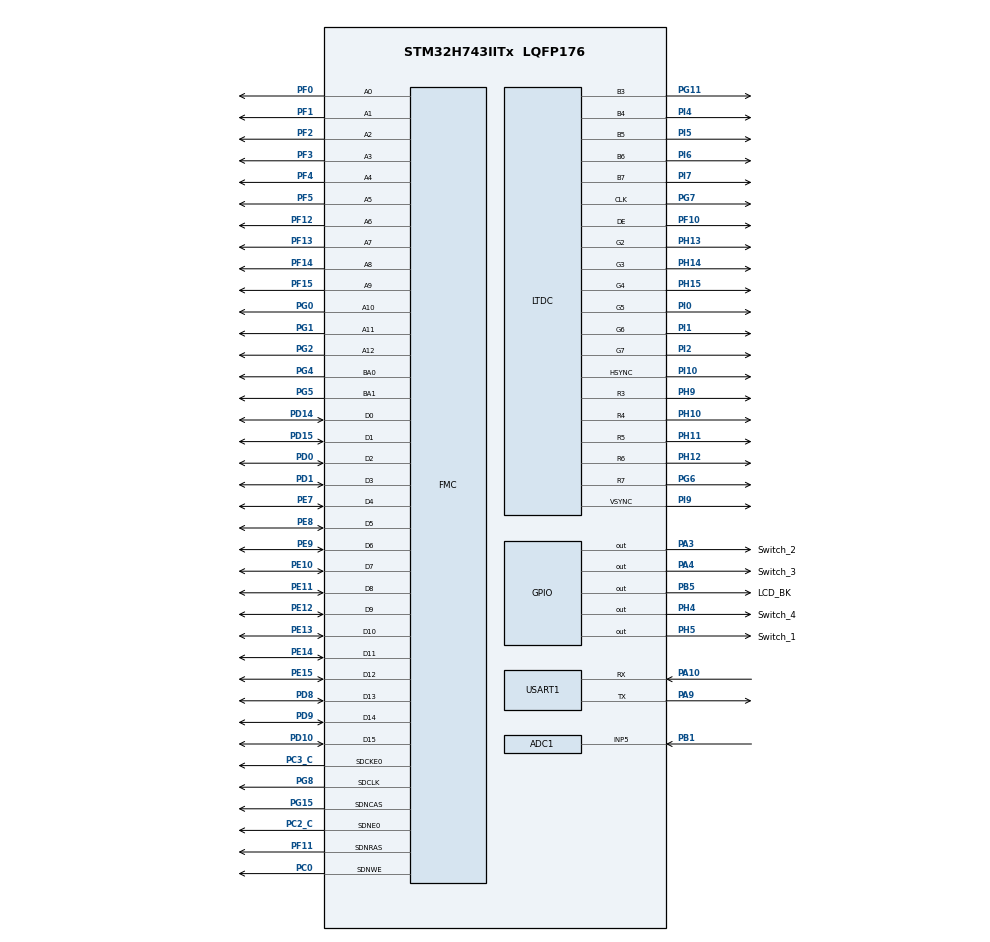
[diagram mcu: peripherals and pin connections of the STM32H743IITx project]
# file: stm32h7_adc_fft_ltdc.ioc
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ADC1.Channel-5\#ChannelRegularConversion=ADC_CHANNEL_5
ADC1.ClockPrescaler=ADC_CLOCK_ASYNC_DIV4
ADC1.ContinuousConvMode=DISABLE
ADC1.ConversionDataManagement=ADC_CONVERSIONDATA_DMA_CIRCULAR
ADC1.EOCSelection=ADC_EOC_SEQ_CONV
ADC1.ExternalTrigConv=ADC_EXTERNALTRIG_T3_TRGO
ADC1.NbrOfConversion=1
ADC1.NbrOfConversionFlag=1
ADC1.OffsetNumber-5\#ChannelRegularConversion=ADC_OFFSET_NONE
ADC1.OffsetSignedSaturation-5\#ChannelRegularConversion=DISABLE
ADC1.Overrun=ADC_OVR_DATA_OVERWRITTEN
ADC1.OversamplingMode=DISABLE
ADC1.Rank-5\#ChannelRegularConversion=1
ADC1.Resolution=ADC_RESOLUTION_16B
ADC1.SamplingTime-5\#ChannelRegularConversion=ADC_SAMPLETIME_64CYCLES_5
ADC1.master=1
CORTEX_M7.CPU_DCache=Disabled
CORTEX_M7.CPU_ICache=Disabled
CORTEX_M7.MPU_Control=__NULL
CORTEX_M7.default_mode_Activation=1
DMA2D.ColorMode=DMA2D_OUTPUT_RGB565
Dma.ADC1.0.Direction=DMA_PERIPH_TO_MEMORY
Dma.ADC1.0.EventEnable=DISABLE
Dma.ADC1.0.FIFOMode=DMA_FIFOMODE_DISABLE
Dma.ADC1.0.Instance=DMA1_Stream0
Dma.ADC1.0.MemDataAlignment=DMA_MDATAALIGN_HALFWORD
Dma.ADC1.0.MemInc=DMA_MINC_ENABLE
Dma.ADC1.0.Mode=DMA_NORMAL
Dma.ADC1.0.PeriphDataAlignment=DMA_PDATAALIGN_HALFWORD
Dma.ADC1.0.PeriphInc=DMA_PINC_DISABLE
Dma.ADC1.0.Polarity=HAL_DMAMUX_REQ_GEN_RISING
Dma.ADC1.0.Priority=DMA_PRIORITY_LOW
Dma.ADC1.0.RequestNumber=1
Dma.ADC1.0.SignalID=NONE
Dma.ADC1.0.SyncEnable=DISABLE
Dma.ADC1.0.SyncPolarity=HAL_DMAMUX_SYNC_NO_EVENT
Dma.ADC1.0.SyncRequestNumber=1
Dma.ADC1.0.SyncSignalID=NONE
Dma.Request0=ADC1
FMC.CASLatency1=FMC_SDRAM_CAS_LATENCY_3
FMC.ColumnBitsNumber1=FMC_SDRAM_COLUMN_BITS_NUM_9
FMC.ExitSelfRefreshDelay1=8
FMC.LoadToActiveDelay1=2
FMC.RCDDelay1=2
FMC.RPDelay1=2
FMC.ReadBurst1=FMC_SDRAM_RBURST_ENABLE
FMC.ReadPipeDelay1=FMC_SDRAM_RPIPE_DELAY_1
FMC.RowCycleDelay1=7
FMC.RowCycleDelay2=7
FMC.SDClockPeriod1=FMC_SDRAM_CLOCK_PERIOD_2
FMC.SelfRefreshTime1=6
FMC.WriteRecoveryTime1=5
LTDC.ActiveH=PIXELS_H
LTDC.ActiveW=PIXELS_W
LTDC.Alpha_L0=255
LTDC.Blue=0
LTDC.Blue_L0=0
LTDC.FBStartAdress_L0=0xc0000000
LTDC.Green=0
LTDC.HBP=140
LTDC.HFP=160
LTDC.HSync=20
LTDC.ImageHeight_L0=600
LTDC.ImageWidth_L0=1024
LTDC.Layers=0
LTDC.PixelFormat_L0=LTDC_PIXEL_FORMAT_RGB565
LTDC.Red=0
LTDC.VBP=20
LTDC.VFP=12
LTDC.VSync=3
LTDC.WindowX1_L0=PIXELS_W
LTDC.WindowY1_L0=PIXELS_H
Mcu.Family=STM32H7
Mcu.Name=STM32H743IITx
Mcu.Package=LQFP176
Mcu.UserConstants=PIXELS_DIR,1;PIXELS_H,600;PIXELS_W,1024;LTDC_BUFF_ADDR,0XC0000000
NVIC.ADC_IRQn=true\:0\:0\:false\:false\:true\:true\:true\:true
NVIC.DMA1_Stream0_IRQn=true\:2\:0\:true\:false\:true\:true\:true\:true
NVIC.DMA2D_IRQn=true\:0\:0\:false\:false\:true\:true\:true\:true
NVIC.PriorityGroup=NVIC_PRIORITYGROUP_4
NVIC.USART1_IRQn=true\:0\:0\:false\:false\:true\:true\:true\:true
PA10.Mode=Asynchronous
PA10.Signal=USART1_RX
PA3.GPIO_Label=Switch_2
PA3.GPIO_PuPd=GPIO_PULLDOWN
PA3.Signal=GPIO_Output
PA4.GPIO_Label=Switch_3
PA4.GPIO_PuPd=GPIO_PULLDOWN
PA4.Signal=GPIO_Output
PA9.Mode=Asynchronous
PA9.Signal=USART1_TX
PB0.Signal=ADCx_INN5
PB1.Signal=ADCx_INP5
PB5.GPIO_Label=LCD_BK
PB5.GPIO_PuPd=GPIO_PULLDOWN
PB5.Signal=GPIO_Output
PC0.Signal=FMC_SDNWE
PC14-OSC32_IN\ (OSC32_IN).Mode=LSE-External-Oscillator
PC14-OSC32_IN\ (OSC32_IN).Signal=RCC_OSC32_IN
PC15-OSC32_OUT\ (OSC32_OUT).Mode=LSE-External-Oscillator
PC15-OSC32_OUT\ (OSC32_OUT).Signal=RCC_OSC32_OUT
PC2_C.Mode=SdramChipSelect1_1
PC2_C.Signal=FMC_SDNE0
PC3_C.Mode=SdramChipSelect1_1
PC3_C.Signal=FMC_SDCKE0
PD0.Signal=FMC_D2_DA2
PD1.Signal=FMC_D3_DA3
PD10.Signal=FMC_D15_DA15
PD14.Signal=FMC_D0_DA0
PD15.Signal=FMC_D1_DA1
PD8.Signal=FMC_D13_DA13
PD9.Signal=FMC_D14_DA14
PE0.Signal=FMC_NBL0
PE1.Signal=FMC_NBL1
PE10.Signal=FMC_D7_DA7
PE11.Signal=FMC_D8_DA8
PE12.Signal=FMC_D9_DA9
PE13.Signal=FMC_D10_DA10
PE14.Signal=FMC_D11_DA11
PE15.Signal=FMC_D12_DA12
PE7.Signal=FMC_D4_DA4
PE8.Signal=FMC_D5_DA5
PE9.Signal=FMC_D6_DA6
PF0.Signal=FMC_A0
PF1.Signal=FMC_A1
PF10.GPIO_Speed=GPIO_SPEED_FREQ_VERY_HIGH
PF10.Mode=RGB565
PF10.Signal=LTDC_DE
PF11.Signal=FMC_SDNRAS
PF12.Signal=FMC_A6
PF13.Signal=FMC_A7
PF14.Signal=FMC_A8
PF15.Signal=FMC_A9
PF2.Signal=FMC_A2
PF3.Signal=FMC_A3
PF4.Signal=FMC_A4
PF5.Signal=FMC_A5
PG0.Signal=FMC_A10
PG1.Signal=FMC_A11
PG11.GPIO_Speed=GPIO_SPEED_FREQ_VERY_HIGH
PG11.Mode=RGB565
PG11.Signal=LTDC_B3
PG15.Signal=FMC_SDNCAS
PG2.Signal=FMC_A12
PG4.Signal=FMC_A14_BA0
PG5.Signal=FMC_A15_BA1
PG6.GPIO_Speed=GPIO_SPEED_FREQ_VERY_HIGH
PG6.Mode=RGB565
PG6.Signal=LTDC_R7
PG7.GPIO_Speed=GPIO_SPEED_FREQ_VERY_HIGH
PG7.Mode=RGB565
PG7.Signal=LTDC_CLK
PG8.Signal=FMC_SDCLK
PH0-OSC_IN\ (PH0).Mode=HSE-External-Oscillator
PH0-OSC_IN\ (PH0).Signal=RCC_OSC_IN
PH1-OSC_OUT\ (PH1).Mode=HSE-External-Oscillator
PH1-OSC_OUT\ (PH1).Signal=RCC_OSC_OUT
PH10.GPIO_Speed=GPIO_SPEED_FREQ_VERY_HIGH
PH10.Mode=RGB565
PH10.Signal=LTDC_R4
PH11.GPIO_Speed=GPIO_SPEED_FREQ_VERY_HIGH
PH11.Mode=RGB565
PH11.Signal=LTDC_R5
PH12.GPIO_Speed=GPIO_SPEED_FREQ_VERY_HIGH
PH12.Mode=RGB565
PH12.Signal=LTDC_R6
PH13.GPIO_Speed=GPIO_SPEED_FREQ_VERY_HIGH
PH13.Mode=RGB565
PH13.Signal=LTDC_G2
PH14.GPIO_Speed=GPIO_SPEED_FREQ_VERY_HIGH
PH14.Mode=RGB565
PH14.Signal=LTDC_G3
PH15.GPIO_Speed=GPIO_SPEED_FREQ_VERY_HIGH
PH15.Mode=RGB565
PH15.Signal=LTDC_G4
PH4.GPIO_Label=Switch_4
PH4.GPIO_PuPd=GPIO_PULLDOWN
PH4.Signal=GPIO_Output
PH5.GPIO_Label=Switch_1
PH5.GPIO_PuPd=GPIO_PULLDOWN
PH5.Signal=GPIO_Output
PH9.GPIO_Speed=GPIO_SPEED_FREQ_VERY_HIGH
PH9.Mode=RGB565
PH9.Signal=LTDC_R3
PI0.GPIO_Speed=GPIO_SPEED_FREQ_VERY_HIGH
PI0.Mode=RGB565
PI0.Signal=LTDC_G5
PI1.GPIO_Speed=GPIO_SPEED_FREQ_VERY_HIGH
PI1.Mode=RGB565
PI1.Signal=LTDC_G6
PI10.GPIO_Speed=GPIO_SPEED_FREQ_VERY_HIGH
PI10.Mode=RGB565
PI10.Signal=LTDC_HSYNC
PI2.GPIO_Speed=GPIO_SPEED_FREQ_VERY_HIGH
PI2.Mode=RGB565
PI2.Signal=LTDC_G7
PI4.GPIO_Speed=GPIO_SPEED_FREQ_VERY_HIGH
PI4.Mode=RGB565
PI4.Signal=LTDC_B4
PI5.GPIO_Speed=GPIO_SPEED_FREQ_VERY_HIGH
PI5.Mode=RGB565
PI5.Signal=LTDC_B5
PI6.GPIO_Speed=GPIO_SPEED_FREQ_VERY_HIGH
PI6.Mode=RGB565
PI6.Signal=LTDC_B6
PI7.GPIO_Speed=GPIO_SPEED_FREQ_VERY_HIGH
PI7.Mode=RGB565
PI7.Signal=LTDC_B7
PI9.GPIO_Speed=GPIO_SPEED_FREQ_VERY_HIGH
PI9.Mode=RGB565
PI9.Signal=LTDC_VSYNC
ProjectManager.HeapSize=0x600
ProjectManager.StackSize=0x600
ProjectManager.TargetToolchain=STM32CubeIDE
RCC.ADCFreq_Value=72000000
RCC.APB1Freq_Value=120000000
RCC.APB2Freq_Value=120000000
RCC.APB3Freq_Value=120000000
RCC.APB4Freq_Value=120000000
RCC.CKPERSourceSelection=RCC_CLKPSOURCE_HSE
RCC.CortexFreq_Value=480000000
RCC.D1PPRE=RCC_APB3_DIV2
RCC.D2PPRE1=RCC_APB1_DIV2
RCC.D2PPRE2=RCC_APB2_DIV2
RCC.D3PPRE=RCC_APB4_DIV2
RCC.DIVM1=5
RCC.DIVM2=5
RCC.DIVM3=1
RCC.DIVN1=192
RCC.DIVN2=72
RCC.DIVN3=9
RCC.DIVP2=5
RCC.DIVR3=5
RCC.HCLKFreq_Value=240000000
RCC.HPRE=RCC_HCLK_DIV2
RCC.PLL2FRACN=0
RCC.PLL3FRACN=0
RCC.PLLFRACN=0
RCC.PLLSourceVirtual=RCC_PLLSOURCE_HSE
RCC.PWR_Regulator_Voltage_Scale=PWR_REGULATOR_VOLTAGE_SCALE0
RCC.SYSCLKFreq_VALUE=480000000
RCC.SYSCLKSource=RCC_SYSCLKSOURCE_PLLCLK
RCC.USBFreq_Value=480000000
SH.ADCx_INN5.0=ADC1_INN5
SH.ADCx_INP5.0=ADC1_INP5,IN5-Single-Ended
SH.FMC_A0.0=FMC_A0,13b-sda1
SH.FMC_A1.0=FMC_A1,13b-sda1
SH.FMC_A10.0=FMC_A10,13b-sda1
SH.FMC_A11.0=FMC_A11,13b-sda1
SH.FMC_A12.0=FMC_A12,13b-sda1
SH.FMC_A14_BA0.0=FMC_BA0,FourSdramBanks1
SH.FMC_A15_BA1.0=FMC_BA1,FourSdramBanks1
SH.FMC_A2.0=FMC_A2,13b-sda1
SH.FMC_A3.0=FMC_A3,13b-sda1
SH.FMC_A4.0=FMC_A4,13b-sda1
SH.FMC_A5.0=FMC_A5,13b-sda1
SH.FMC_A6.0=FMC_A6,13b-sda1
SH.FMC_A7.0=FMC_A7,13b-sda1
SH.FMC_A8.0=FMC_A8,13b-sda1
SH.FMC_A9.0=FMC_A9,13b-sda1
SH.FMC_D0_DA0.0=FMC_D0,sd-16b-d1
SH.FMC_D10_DA10.0=FMC_D10,sd-16b-d1
SH.FMC_D11_DA11.0=FMC_D11,sd-16b-d1
SH.FMC_D12_DA12.0=FMC_D12,sd-16b-d1
SH.FMC_D13_DA13.0=FMC_D13,sd-16b-d1
SH.FMC_D14_DA14.0=FMC_D14,sd-16b-d1
SH.FMC_D15_DA15.0=FMC_D15,sd-16b-d1
SH.FMC_D1_DA1.0=FMC_D1,sd-16b-d1
SH.FMC_D2_DA2.0=FMC_D2,sd-16b-d1
SH.FMC_D3_DA3.0=FMC_D3,sd-16b-d1
SH.FMC_D4_DA4.0=FMC_D4,sd-16b-d1
SH.FMC_D5_DA5.0=FMC_D5,sd-16b-d1
SH.FMC_D6_DA6.0=FMC_D6,sd-16b-d1
SH.FMC_D7_DA7.0=FMC_D7,sd-16b-d1
SH.FMC_D8_DA8.0=FMC_D8,sd-16b-d1
SH.FMC_D9_DA9.0=FMC_D9,sd-16b-d1
SH.FMC_NBL0.0=FMC_NBL0
SH.FMC_NBL1.0=FMC_NBL1
SH.FMC_SDCLK.0=FMC_SDCLK,13b-sda1
SH.FMC_SDNCAS.0=FMC_SDNCAS,13b-sda1
SH.FMC_SDNRAS.0=FMC_SDNRAS,13b-sda1
SH.FMC_SDNWE.0=FMC_SDNWE,13b-sda1
STMicroelectronics.X-CUBE-ALGOBUILD.1.3.0.LibraryCcDSPOoLibraryJjDSPOoLibrary=true
TIM3.Period=5-1
TIM3.Prescaler=375-1
TIM3.TIM_MasterOutputTrigger=TIM_TRGO_UPDATE
USART1.VirtualMode-Asynchronous=VM_ASYNC
VP_DMA2D_VS_DMA2D.Mode=DMA2D_Activate
VP_STMicroelectronics.X-CUBE-ALGOBUILD_VS_DSPOoLibraryJjLibrary_1.3.0_1.3.0.Mode=DSPOoLibraryJjLibrary
VP_TIM3_VS_ClockSourceINT.Mode=Internal
board=custom

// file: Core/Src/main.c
/* USER CODE BEGIN Header */
/**
  ******************************************************************************
  * @file           : main.c
  * @brief          : Main program body
  ******************************************************************************
  * @attention
  *
  * Copyright (c) 2023 STMicroelectronics.
  * All rights reserved.
  *
  * This software is licensed under terms that can be found in the LICENSE file
  * in the root directory of this software component.
  * If no LICENSE file comes with this software, it is provided AS-IS.
  *
  ******************************************************************************
  */
/* USER CODE END Header */
#include "main.h"
#include "adc.h"
#include "dma.h"
#include "dma2d.h"
#include "ltdc.h"
#include "tim.h"
#include "usart.h"
#include "gpio.h"
#include "fmc.h"

/* USER CODE BEGIN Includes */
#include "stdio.h"
#include "lvgl.h"
#include "lv_port_disp.h"
#include "lv_port_indev.h"
#include "ui.h"
#include "arm_math.h"
#include "arm_const_structs.h"

/* USER CODE END Includes */

/* USER CODE BEGIN PD */

#define ADC1_BUFFER_SIZE 1024	//ADC1用了4通道, 存32组, 方便做平均
#define sqrt2 1.4142135623730950488
//32字节对齐(地址+大小)
//adc1_data指定到 AXI SRAM 的0x24000000
//adc3_data指定到 SRAM4 的0x38000000
ALIGN_32BYTES (uint16_t adc1_data[ADC1_BUFFER_SIZE]) __attribute__((section(".ARM.__at_0x24000000")));

/* USER CODE END PD */

/* USER CODE BEGIN PV */
uint8_t ADC_STOP=0;
uint32_t fft_max_index;
float32_t maxValue;
float32_t fft_input[ADC1_BUFFER_SIZE*2];
float32_t fft_output[ADC1_BUFFER_SIZE];

float32_t THD;
char thd_text[30]={0};
/* USER CODE END PV */

void SystemClock_Config(void);
/* USER CODE BEGIN PFP */
void GetTHD();
/* USER CODE END PFP */

int main(void)
{

  /* MCU Configuration--------------------------------------------------------*/

  /* Reset of all peripherals, Initializes the Flash interface and the Systick. */
  HAL_Init();

  /* Configure the system clock */
  SystemClock_Config();

  /* Initialize all configured peripherals */
  MX_GPIO_Init();
  MX_FMC_Init();
  MX_USART1_UART_Init();
  MX_DMA2D_Init();
  MX_LTDC_Init();
  MX_DMA_Init();
  MX_ADC1_Init();
  MX_TIM3_Init();
  /* USER CODE BEGIN 2 */
    SDRAM_InitSequence();
    lv_init();
    lv_port_disp_init();
    lv_port_indev_init();
    ui_init();
    HAL_TIM_Base_Start(&htim3);
//    HAL_TIM_Base_Start_IT(&htim3);

    if(HAL_ADCEx_Calibration_Start(&hadc1,ADC_CALIB_OFFSET,ADC_SINGLE_ENDED)!=HAL_OK)
    {
        printf("hadc1 error with HAL_ADCEx_Calibration_Start\r\n");
        Error_Handler();
    }
    if (HAL_ADC_Start_DMA(&hadc1, (uint32_t *)adc1_data, ADC1_BUFFER_SIZE) != HAL_OK)
    {
        printf("hadc1 error with HAL_ADC_Start_DMA\r\n");
        Error_Handler();
    }

//    arm_status status;
//    status = ARM_MATH_SUCCESS;

    printf("start\r\n");
  /* USER CODE END 2 */

  /* Infinite loop */
  /* USER CODE BEGIN WHILE */
  while (1)
  {
      lv_task_handler();

      for (int i = 0; i < ADC1_BUFFER_SIZE; i++) {
          fft_input[i * 2] = (adc1_data[i] * 2.0 / 65535.0-1.0) * 3.3;
          fft_input[2 * i + 1] = 0;
      }
      for(int i=0;i<1024;i++) {
          printf("%f,%d\n",fft_input[i*2],i);
      }

//      lv_task_handler();
      arm_cfft_f32(&arm_cfft_sR_f32_len1024,fft_input,0,1);
      arm_cmplx_mag_f32(fft_input,fft_output,ADC1_BUFFER_SIZE);
      arm_max_f32(fft_output,ADC1_BUFFER_SIZE,&maxValue,&fft_max_index);
      lv_task_handler();

      for(int i=0;i<512;i++) {
          if (i) {
              fft_output[i] = fft_output[i] / 512.0;
//                  printf("%lf,%d\n",fft_output[i],i);
          } else fft_output[i] = fft_output[i] / 1024.0;
      }

      GetTHD();
      sprintf(thd_text,"%.3f %%",THD);
      lv_label_set_text(lable_chthd,thd_text);
//      HAL_ADCEx_Calibration_Start(&hadc1,ADC_CALIB_OFFSET,ADC_SINGLE_ENDED);
      HAL_ADC_Start_DMA(&hadc1, (uint32_t *)adc1_data, ADC1_BUFFER_SIZE);
      lv_task_handler();

    /* USER CODE END WHILE */

  }
}

void SystemClock_Config(void)
{
  RCC_OscInitTypeDef RCC_OscInitStruct = {0};
  RCC_ClkInitTypeDef RCC_ClkInitStruct = {0};

  /** Supply configuration update enable
  */
  HAL_PWREx_ConfigSupply(PWR_LDO_SUPPLY);

  /** Configure the main internal regulator output voltage
  */
  __HAL_PWR_VOLTAGESCALING_CONFIG(PWR_REGULATOR_VOLTAGE_SCALE1);

  while(!__HAL_PWR_GET_FLAG(PWR_FLAG_VOSRDY)) {}

  __HAL_RCC_SYSCFG_CLK_ENABLE();
  __HAL_PWR_VOLTAGESCALING_CONFIG(PWR_REGULATOR_VOLTAGE_SCALE0);

  while(!__HAL_PWR_GET_FLAG(PWR_FLAG_VOSRDY)) {}

  /** Macro to configure the PLL clock source
  */
  __HAL_RCC_PLL_PLLSOURCE_CONFIG(RCC_PLLSOURCE_HSE);

  /** Initializes the RCC Oscillators according to the specified parameters
  * in the RCC_OscInitTypeDef structure.
  */
  RCC_OscInitStruct.OscillatorType = RCC_OSCILLATORTYPE_HSE;
  RCC_OscInitStruct.HSEState = RCC_HSE_ON;
  RCC_OscInitStruct.PLL.PLLState = RCC_PLL_ON;
  RCC_OscInitStruct.PLL.PLLSource = RCC_PLLSOURCE_HSE;
  RCC_OscInitStruct.PLL.PLLM = 5;
  RCC_OscInitStruct.PLL.PLLN = 192;
  RCC_OscInitStruct.PLL.PLLP = 2;
  RCC_OscInitStruct.PLL.PLLQ = 2;
  RCC_OscInitStruct.PLL.PLLR = 2;
  RCC_OscInitStruct.PLL.PLLRGE = RCC_PLL1VCIRANGE_2;
  RCC_OscInitStruct.PLL.PLLVCOSEL = RCC_PLL1VCOWIDE;
  RCC_OscInitStruct.PLL.PLLFRACN = 0;
  if (HAL_RCC_OscConfig(&RCC_OscInitStruct) != HAL_OK)
  {
    Error_Handler();
  }

  /** Initializes the CPU, AHB and APB buses clocks
  */
  RCC_ClkInitStruct.ClockType = RCC_CLOCKTYPE_HCLK|RCC_CLOCKTYPE_SYSCLK
                              |RCC_CLOCKTYPE_PCLK1|RCC_CLOCKTYPE_PCLK2
                              |RCC_CLOCKTYPE_D3PCLK1|RCC_CLOCKTYPE_D1PCLK1;
  RCC_ClkInitStruct.SYSCLKSource = RCC_SYSCLKSOURCE_PLLCLK;
  RCC_ClkInitStruct.SYSCLKDivider = RCC_SYSCLK_DIV1;
  RCC_ClkInitStruct.AHBCLKDivider = RCC_HCLK_DIV2;
  RCC_ClkInitStruct.APB3CLKDivider = RCC_APB3_DIV2;
  RCC_ClkInitStruct.APB1CLKDivider = RCC_APB1_DIV2;
  RCC_ClkInitStruct.APB2CLKDivider = RCC_APB2_DIV2;
  RCC_ClkInitStruct.APB4CLKDivider = RCC_APB4_DIV2;

  if (HAL_RCC_ClockConfig(&RCC_ClkInitStruct, FLASH_LATENCY_4) != HAL_OK)
  {
    Error_Handler();
  }
}

/* USER CODE BEGIN 4 */

void HAL_ADC_ConvHalfCpltCallback(ADC_HandleTypeDef* hadc)
{
    /* Invalidate Data Cache to get the updated content of the SRAM on the first half of the ADC converted data buffer */
    if(hadc->Instance == ADC1) {
//        SCB_InvalidateDCache_by_Addr((uint32_t *) &adc1_data[0], ADC1_BUFFER_SIZE);
    }
}

void HAL_ADC_ConvCpltCallback(ADC_HandleTypeDef* hadc)
{

    /* Invalidate Data Cache to get the updated content of the SRAM on the second half of the ADC converted data buffer */
    if(hadc->Instance == ADC1) {
//        ADC_STOP=1;
        HAL_ADC_Stop_DMA(&hadc1);

//        lv_task_handler();
//        SCB_InvalidateDCache_by_Addr((uint32_t *) &adc1_data[ADC1_BUFFER_SIZE/2], ADC1_BUFFER_SIZE);
    }
}

void GetTHD(){
    //计算第8个点，第16个点，第32个点，第64个点，第128个点
    THD=sqrt((fft_output[16]/sqrt2)*(fft_output[16]/sqrt2)+(fft_output[32]/sqrt2)*(fft_output[32]/sqrt2)+(fft_output[64]/sqrt2)*(fft_output[64]/sqrt2)+(fft_output[128]/sqrt2)*(fft_output[128]/sqrt2)+(fft_output[256]/sqrt2)*(fft_output[256]/sqrt2))/((fft_output[8]/sqrt2)*(fft_output[8]/sqrt2));
}

/* USER CODE END 4 */

void Error_Handler(void)
{
  __disable_irq();
  while (1)
  {
  }
}
